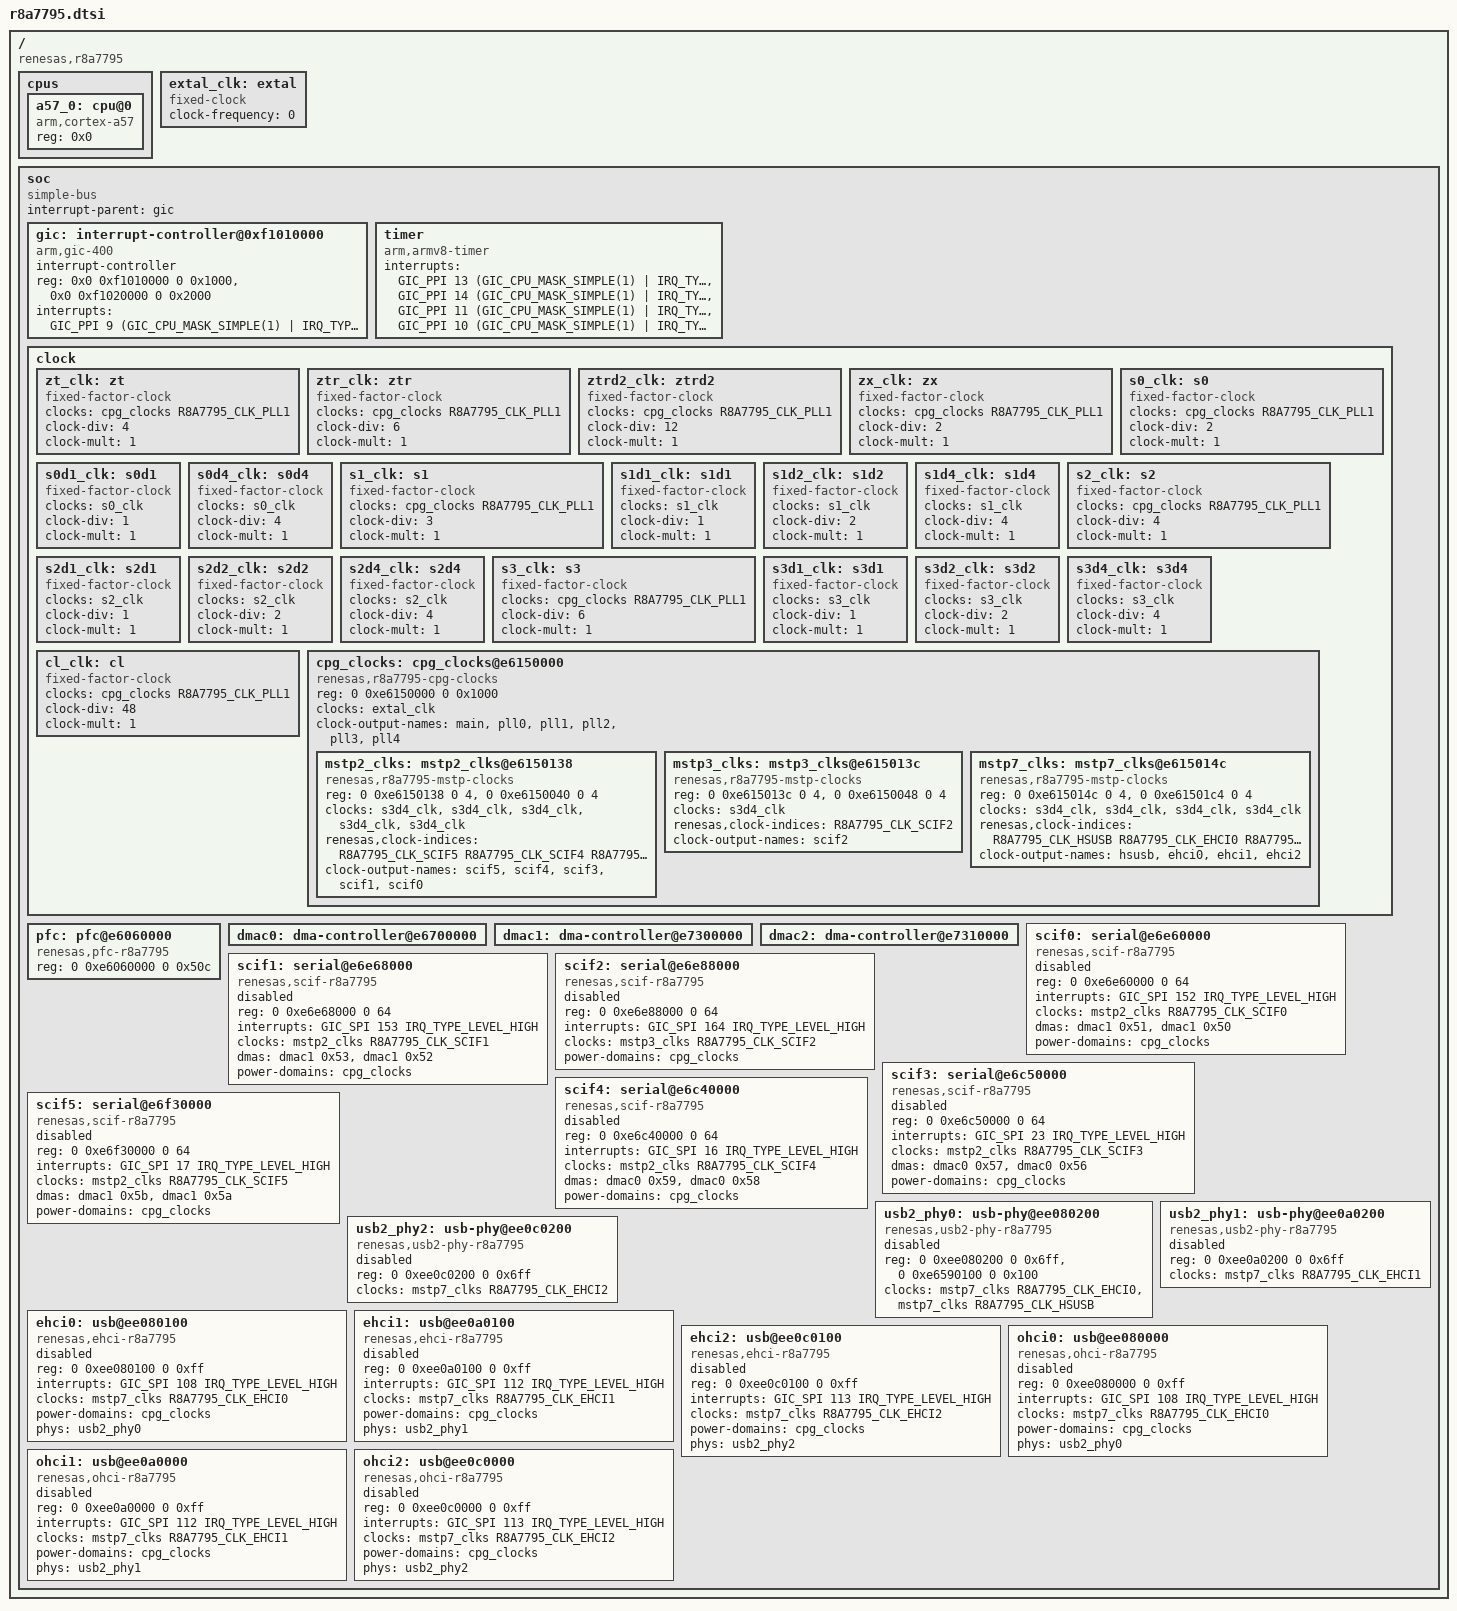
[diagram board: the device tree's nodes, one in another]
/*
 * Device Tree Source for the r8a7795 SoC
 *
 * Copyright (C) 2015 Renesas Electronics Corp.
 *
 * This file is licensed under the terms of the GNU General Public License
 * version 2.  This program is licensed "as is" without any warranty of any
 * kind, whether express or implied.
 */

#include <dt-bindings/clock/r8a7795-clock.h>
#include <dt-bindings/interrupt-controller/arm-gic.h>

/ {
	compatible = "renesas,r8a7795";
	#address-cells = <2>;
	#size-cells = <2>;

	cpus {
		#address-cells = <1>;
		#size-cells = <0>;

		/* 1core only at this point */
		a57_0: cpu@0 {
			compatible = "arm,cortex-a57", "arm,armv8";
			reg = <0x0>;
			device_type = "cpu";
		};
	};

	extal_clk: extal {
		compatible = "fixed-clock";
		#clock-cells = <0>;
		/* This value must be overridden by the board */
		clock-frequency = <0>;
	};

	soc {
		compatible = "simple-bus";
		interrupt-parent = <&gic>;
		#address-cells = <2>;
		#size-cells = <2>;
		ranges;

		gic: interrupt-controller@0xf1010000 {
			compatible = "arm,gic-400";
			#interrupt-cells = <3>;
			#address-cells = <0>;
			interrupt-controller;
			reg = <0x0 0xf1010000 0 0x1000>,
			      <0x0 0xf1020000 0 0x2000>;
			interrupts = <GIC_PPI 9
					(GIC_CPU_MASK_SIMPLE(1) | IRQ_TYPE_LEVEL_HIGH)>;
		};

		timer {
			compatible = "arm,armv8-timer";
			interrupts = <GIC_PPI 13
					(GIC_CPU_MASK_SIMPLE(1) | IRQ_TYPE_LEVEL_LOW)>,
				     <GIC_PPI 14
					(GIC_CPU_MASK_SIMPLE(1) | IRQ_TYPE_LEVEL_LOW)>,
				     <GIC_PPI 11
					(GIC_CPU_MASK_SIMPLE(1) | IRQ_TYPE_LEVEL_LOW)>,
				     <GIC_PPI 10
					(GIC_CPU_MASK_SIMPLE(1) | IRQ_TYPE_LEVEL_LOW)>;
		};

		clock {
			#address-cells = <2>;
			#size-cells = <2>;
			#clock-cells = <1>;
			ranges;

			zt_clk: zt {
				compatible = "fixed-factor-clock";
				clocks = <&cpg_clocks R8A7795_CLK_PLL1>;
				#clock-cells = <0>;
				clock-div = <4>;
				clock-mult = <1>;
			};

			ztr_clk: ztr {
				compatible = "fixed-factor-clock";
				clocks = <&cpg_clocks R8A7795_CLK_PLL1>;
				#clock-cells = <0>;
				clock-div = <6>;
				clock-mult = <1>;
			};

			ztrd2_clk: ztrd2 {
				compatible = "fixed-factor-clock";
				clocks = <&cpg_clocks R8A7795_CLK_PLL1>;
				#clock-cells = <0>;
				clock-div = <12>;
				clock-mult = <1>;
			};

			zx_clk: zx {
				compatible = "fixed-factor-clock";
				clocks = <&cpg_clocks R8A7795_CLK_PLL1>;
				#clock-cells = <0>;
				clock-div = <2>;
				clock-mult = <1>;
			};

			s0_clk: s0 {
				compatible = "fixed-factor-clock";
				clocks = <&cpg_clocks R8A7795_CLK_PLL1>;
				#clock-cells = <0>;
				clock-div = <2>;
				clock-mult = <1>;
			};

			s0d1_clk: s0d1 {
				compatible = "fixed-factor-clock";
				clocks = <&s0_clk>;
				#clock-cells = <0>;
				clock-div = <1>;
				clock-mult = <1>;
			};

			s0d4_clk: s0d4 {
				compatible = "fixed-factor-clock";
				clocks = <&s0_clk>;
				#clock-cells = <0>;
				clock-div = <4>;
				clock-mult = <1>;
			};

			s1_clk: s1 {
				compatible = "fixed-factor-clock";
				clocks = <&cpg_clocks R8A7795_CLK_PLL1>;
				#clock-cells = <0>;
				clock-div = <3>;
				clock-mult = <1>;
			};

			s1d1_clk: s1d1 {
				compatible = "fixed-factor-clock";
				clocks = <&s1_clk>;
				#clock-cells = <0>;
				clock-div = <1>;
				clock-mult = <1>;
			};

			s1d2_clk: s1d2 {
				compatible = "fixed-factor-clock";
				clocks = <&s1_clk>;
				#clock-cells = <0>;
				clock-div = <2>;
				clock-mult = <1>;
			};

			s1d4_clk: s1d4 {
				compatible = "fixed-factor-clock";
				clocks = <&s1_clk>;
				#clock-cells = <0>;
				clock-div = <4>;
				clock-mult = <1>;
			};

			s2_clk: s2 {
				compatible = "fixed-factor-clock";
				clocks = <&cpg_clocks R8A7795_CLK_PLL1>;
				#clock-cells = <0>;
				clock-div = <4>;
				clock-mult = <1>;
			};

			s2d1_clk: s2d1 {
				compatible = "fixed-factor-clock";
				clocks = <&s2_clk>;
				#clock-cells = <0>;
				clock-div = <1>;
				clock-mult = <1>;
			};

			s2d2_clk: s2d2 {
				compatible = "fixed-factor-clock";
				clocks = <&s2_clk>;
				#clock-cells = <0>;
				clock-div = <2>;
				clock-mult = <1>;
			};

			s2d4_clk: s2d4 {
				compatible = "fixed-factor-clock";
				clocks = <&s2_clk>;
				#clock-cells = <0>;
				clock-div = <4>;
				clock-mult = <1>;
			};

			s3_clk: s3 {
				compatible = "fixed-factor-clock";
				clocks = <&cpg_clocks R8A7795_CLK_PLL1>;
				#clock-cells = <0>;
				clock-div = <6>;
				clock-mult = <1>;
			};

			s3d1_clk: s3d1 {
				compatible = "fixed-factor-clock";
				clocks = <&s3_clk>;
				#clock-cells = <0>;
				clock-div = <1>;
				clock-mult = <1>;
			};

			s3d2_clk: s3d2 {
				compatible = "fixed-factor-clock";
				clocks = <&s3_clk>;
				#clock-cells = <0>;
				clock-div = <2>;
				clock-mult = <1>;
			};

			s3d4_clk: s3d4 {
				compatible = "fixed-factor-clock";
				clocks = <&s3_clk>;
				#clock-cells = <0>;
				clock-div = <4>;
				clock-mult = <1>;
			};

			cl_clk: cl {
				compatible = "fixed-factor-clock";
				clocks = <&cpg_clocks R8A7795_CLK_PLL1>;
				#clock-cells = <0>;
				clock-div = <48>;
				clock-mult = <1>;
			};

			cpg_clocks: cpg_clocks@e6150000 {
				#address-cells = <2>;
				#size-cells = <2>;
				#clock-cells = <1>;
				ranges;

				compatible = "renesas,r8a7795-cpg-clocks",
					     "renesas,rcar-gen3-cpg-clocks";
				reg = <0 0xe6150000 0 0x1000>;
				clocks = <&extal_clk>;
				clock-output-names = "main", "pll0", "pll1","pll2",
						     "pll3", "pll4";
				#power-domain-cells = <0>;

				mstp2_clks: mstp2_clks@e6150138 {
					compatible =
						"renesas,r8a7795-mstp-clocks",
						"renesas,cpg-mstp-clocks";
					reg = <0 0xe6150138 0 4>,
					      <0 0xe6150040 0 4>;
					clocks = <&s3d4_clk>, <&s3d4_clk>,
						 <&s3d4_clk>, <&s3d4_clk>,
						 <&s3d4_clk>;
					#clock-cells = <1>;
					renesas,clock-indices = <
						R8A7795_CLK_SCIF5
						R8A7795_CLK_SCIF4
						R8A7795_CLK_SCIF3
						R8A7795_CLK_SCIF1
						R8A7795_CLK_SCIF0
					>;
					clock-output-names =
						"scif5", "scif4", "scif3",
						"scif1", "scif0";
				};

				mstp3_clks: mstp3_clks@e615013c {
					compatible = "renesas,r8a7795-mstp-clocks",
					             "renesas,cpg-mstp-clocks";
					reg = <0 0xe615013c 0 4>, <0 0xe6150048 0 4>;
					clocks =  <&s3d4_clk>;
					#clock-cells = <1>;
					renesas,clock-indices = <R8A7795_CLK_SCIF2>;
					clock-output-names = "scif2";
				};

				mstp7_clks: mstp7_clks@e615014c {
					compatible = "renesas,r8a7795-mstp-clocks",
						     "renesas,cpg-mstp-clocks";
					reg = <0 0xe615014c 0 4>, <0 0xe61501c4 0 4>;
					clocks =  <&s3d4_clk>, <&s3d4_clk>, <&s3d4_clk>,
						  <&s3d4_clk>;
					#clock-cells = <1>;
					renesas,clock-indices = <R8A7795_CLK_HSUSB
								 R8A7795_CLK_EHCI0
								 R8A7795_CLK_EHCI1
								 R8A7795_CLK_EHCI2>;
					clock-output-names = "hsusb", "ehci0", "ehci1", "ehci2";
				};
			};
		};

		pfc: pfc@e6060000 {
			compatible = "renesas,pfc-r8a7795";
			reg = <0 0xe6060000 0 0x50c>;
		};

		dmac0: dma-controller@e6700000 {
			/* Empty node for now */
		};

		dmac1: dma-controller@e7300000 {
			/* Empty node for now */
		};

		dmac2: dma-controller@e7310000 {
			/* Empty node for now */
		};

		scif0: serial@e6e60000 {
			compatible = "renesas,scif-r8a7795", "renesas,scif";
			reg = <0 0xe6e60000 0 64>;
			interrupts = <GIC_SPI 152 IRQ_TYPE_LEVEL_HIGH>;
			clocks = <&mstp2_clks R8A7795_CLK_SCIF0>;
			clock-names = "sci_ick";
			dmas = <&dmac1 0x51>, <&dmac1 0x50>;
			dma-names = "tx", "rx";
			power-domains = <&cpg_clocks>;
			status = "disabled";
		};

		scif1: serial@e6e68000 {
			compatible = "renesas,scif-r8a7795", "renesas,scif";
			reg = <0 0xe6e68000 0 64>;
			interrupts = <GIC_SPI 153 IRQ_TYPE_LEVEL_HIGH>;
			clocks = <&mstp2_clks R8A7795_CLK_SCIF1>;
			clock-names = "sci_ick";
			dmas = <&dmac1 0x53>, <&dmac1 0x52>;
			dma-names = "tx", "rx";
			power-domains = <&cpg_clocks>;
			status = "disabled";
		};

		scif2: serial@e6e88000 {
			compatible = "renesas,scif-r8a7795", "renesas,scif";
			reg = <0 0xe6e88000 0 64>;
			interrupts = <GIC_SPI 164 IRQ_TYPE_LEVEL_HIGH>;
			clocks = <&mstp3_clks R8A7795_CLK_SCIF2>;
			clock-names = "sci_ick";
			power-domains = <&cpg_clocks>;
			status = "disabled";
		};

		scif3: serial@e6c50000 {
			compatible = "renesas,scif-r8a7795", "renesas,scif";
			reg = <0 0xe6c50000 0 64>;
			interrupts = <GIC_SPI 23 IRQ_TYPE_LEVEL_HIGH>;
			clocks = <&mstp2_clks R8A7795_CLK_SCIF3>;
			clock-names = "sci_ick";
			dmas = <&dmac0 0x57>, <&dmac0 0x56>;
			dma-names = "tx", "rx";
			power-domains = <&cpg_clocks>;
			status = "disabled";
		};

		scif4: serial@e6c40000 {
			compatible = "renesas,scif-r8a7795", "renesas,scif";
			reg = <0 0xe6c40000 0 64>;
			interrupts = <GIC_SPI 16 IRQ_TYPE_LEVEL_HIGH>;
			clocks = <&mstp2_clks R8A7795_CLK_SCIF4>;
			clock-names = "sci_ick";
			dmas = <&dmac0 0x59>, <&dmac0 0x58>;
			dma-names = "tx", "rx";
			power-domains = <&cpg_clocks>;
			status = "disabled";
		};

		scif5: serial@e6f30000 {
			compatible = "renesas,scif-r8a7795", "renesas,scif";
			reg = <0 0xe6f30000 0 64>;
			interrupts = <GIC_SPI 17 IRQ_TYPE_LEVEL_HIGH>;
			clocks = <&mstp2_clks R8A7795_CLK_SCIF5>;
			clock-names = "sci_ick";
			dmas = <&dmac1 0x5b>, <&dmac1 0x5a>;
			dma-names = "tx", "rx";
			power-domains = <&cpg_clocks>;
			status = "disabled";
		};

		usb2_phy0: usb-phy@ee080200 {
			compatible = "renesas,usb2-phy-r8a7795";
			reg = <0 0xee080200 0 0x6ff>, <0 0xe6590100 0 0x100>;
			reg-names = "usb2", "hsusb";
			clocks = <&mstp7_clks R8A7795_CLK_EHCI0>,
				 <&mstp7_clks R8A7795_CLK_HSUSB>;
			clock-names = "usb2", "hsusb";
			#phy-cells = <0>;
			status = "disabled";
		};

		usb2_phy1: usb-phy@ee0a0200 {
			compatible = "renesas,usb2-phy-r8a7795";
			reg = <0 0xee0a0200 0 0x6ff>;
			reg-names = "usb2";
			clocks = <&mstp7_clks R8A7795_CLK_EHCI1>;
			clock-names = "usb2";
			#phy-cells = <0>;
			status = "disabled";
		};

		usb2_phy2: usb-phy@ee0c0200 {
			compatible = "renesas,usb2-phy-r8a7795";
			reg = <0 0xee0c0200 0 0x6ff>;
			reg-names = "usb2";
			clocks = <&mstp7_clks R8A7795_CLK_EHCI2>;
			clock-names = "usb2";
			#phy-cells = <0>;
			status = "disabled";
		};

		ehci0: usb@ee080100 {
			compatible = "renesas,ehci-r8a7795", "generic-ehci";
			reg = <0 0xee080100 0 0xff>;
			interrupts = <GIC_SPI 108 IRQ_TYPE_LEVEL_HIGH>;
			clocks = <&mstp7_clks R8A7795_CLK_EHCI0>;
			power-domains = <&cpg_clocks>;
			phys = <&usb2_phy0>;
			phy-names = "usb";
			status = "disabled";
		};

		ehci1: usb@ee0a0100 {
			compatible = "renesas,ehci-r8a7795", "generic-ehci";
			reg = <0 0xee0a0100 0 0xff>;
			interrupts = <GIC_SPI 112 IRQ_TYPE_LEVEL_HIGH>;
			clocks = <&mstp7_clks R8A7795_CLK_EHCI1>;
			power-domains = <&cpg_clocks>;
			phys = <&usb2_phy1>;
			phy-names = "usb";
			status = "disabled";
		};

		ehci2: usb@ee0c0100 {
			compatible = "renesas,ehci-r8a7795", "generic-ehci";
			reg = <0 0xee0c0100 0 0xff>;
			interrupts = <GIC_SPI 113 IRQ_TYPE_LEVEL_HIGH>;
			clocks = <&mstp7_clks R8A7795_CLK_EHCI2>;
			power-domains = <&cpg_clocks>;
			phys = <&usb2_phy2>;
			phy-names = "usb";
			status = "disabled";
		};

		ohci0: usb@ee080000 {
			compatible = "renesas,ohci-r8a7795", "generic-ohci";
			reg = <0 0xee080000 0 0xff>;
			interrupts = <GIC_SPI 108 IRQ_TYPE_LEVEL_HIGH>;
			clocks = <&mstp7_clks R8A7795_CLK_EHCI0>;
			power-domains = <&cpg_clocks>;
			phys = <&usb2_phy0>;
			phy-names = "usb";
			status = "disabled";
		};

		ohci1: usb@ee0a0000 {
			compatible = "renesas,ohci-r8a7795", "generic-ohci";
			reg = <0 0xee0a0000 0 0xff>;
			interrupts = <GIC_SPI 112 IRQ_TYPE_LEVEL_HIGH>;
			clocks = <&mstp7_clks R8A7795_CLK_EHCI1>;
			power-domains = <&cpg_clocks>;
			phys = <&usb2_phy1>;
			phy-names = "usb";
			status = "disabled";
		};

		ohci2: usb@ee0c0000 {
			compatible = "renesas,ohci-r8a7795", "generic-ohci";
			reg = <0 0xee0c0000 0 0xff>;
			interrupts = <GIC_SPI 113 IRQ_TYPE_LEVEL_HIGH>;
			clocks = <&mstp7_clks R8A7795_CLK_EHCI2>;
			power-domains = <&cpg_clocks>;
			phys = <&usb2_phy2>;
			phy-names = "usb";
			status = "disabled";
		};
	};
};
